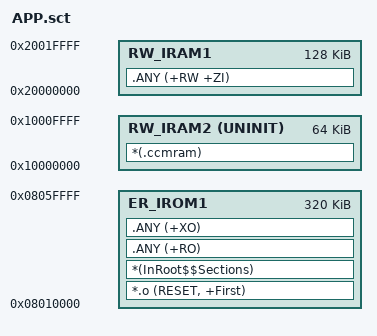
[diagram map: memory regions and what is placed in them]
; *************************************************************
; *** Scatter-Loading Description File generated by uVision ***
; *************************************************************
;
; APP partition: 0x08010000 ~ 0x0805FFFF (320 KB, matches BOOT/boot_config.h RUN)
; The last 8 bytes (0x0805FFF8 magic / 0x0805FFFC version) are NOT linked;
; they are written by the OTA flow or Script/append_app_magic.py before flash.

LR_IROM1 0x08010000 0x00050000  {    ; load region (320 KB RUN)
  ER_IROM1 0x08010000 0x00050000  {  ; load address = execution address
   *.o (RESET, +First)
   *(InRoot$$Sections)
   .ANY (+RO)
   .ANY (+XO)
  }
  RW_IRAM1 0x20000000 0x00020000  {  ; RW data (128 KB main SRAM)
   .ANY (+RW +ZI)
  }
  RW_IRAM2 0x10000000 UNINIT 0x00010000  {  ; CCM RAM 64KB（FreeRTOS 堆/预触发缓冲，CPU-only）
   *(.ccmram)
  }
}
